# STM32F469AEH6 register map
File version: 1.0
Registers are 32-bit, access not given, reset 0x0 unless marked. A register's access mark holds for its fields unless they carry their own. Offsets are from the block's base; [hi:lo] are bit positions; {n}, {i} and the like mark numbered series.

## USART2
Base 0x40004400
Same registers: USART3 0x40004800, UART4 0x40004C00, UART5 0x40005000, UART7 0x40007800, UART8 0x40007C00, USART1 0x40011000, USART6 0x40011400
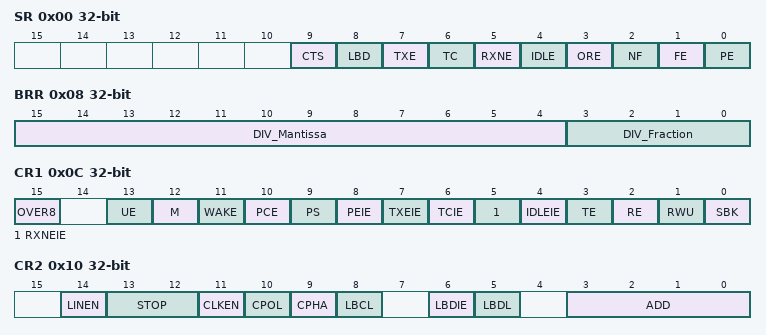
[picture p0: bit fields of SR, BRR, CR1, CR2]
0x00 SR
  [9] CTS, [8] LBD, [7] TXE, [6] TC, [5] RXNE, [4] IDLE, [3] ORE, [2] NF, [1] FE, [0] PE
0x04 DR
  [8:0] DR
0x08 BRR
  [15:4] DIV_Mantissa, [3:0] DIV_Fraction
0x0C CR1
  [15] OVER8, [13] UE, [12] M, [11] WAKE, [10] PCE, [9] PS, [8] PEIE, [7] TXEIE, [6] TCIE, [5] RXNEIE, [4] IDLEIE, [3] TE, [2] RE, [1] RWU, [0] SBK
0x10 CR2
  [14] LINEN, [13:12] STOP, [11] CLKEN, [10] CPOL, [9] CPHA, [8] LBCL, [6] LBDIE, [5] LBDL, [3:0] ADD
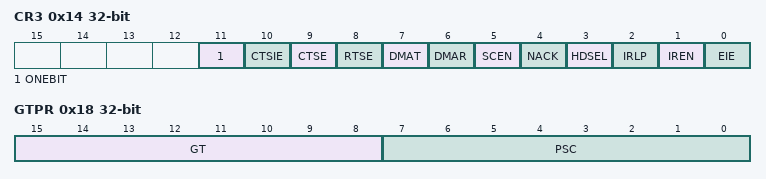
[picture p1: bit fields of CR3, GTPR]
0x14 CR3
  [11] ONEBIT, [10] CTSIE, [9] CTSE, [8] RTSE, [7] DMAT, [6] DMAR, [5] SCEN, [4] NACK, [3] HDSEL, [2] IRLP, [1] IREN, [0] EIE
0x18 GTPR
  [15:8] GT, [7:0] PSC

## I2C1
Base 0x40005400
Same registers: I2C2 0x40005800, I2C3 0x40005C00
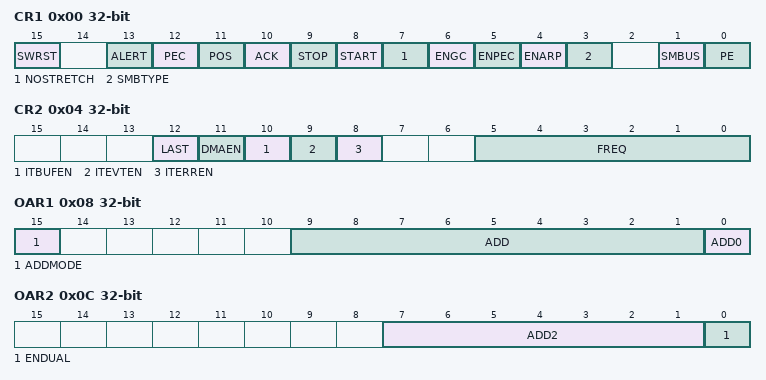
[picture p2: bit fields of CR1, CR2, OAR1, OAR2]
0x00 CR1
  [15] SWRST, [13] ALERT, [12] PEC, [11] POS, [10] ACK, [9] STOP, [8] START, [7] NOSTRETCH, [6] ENGC, [5] ENPEC, [4] ENARP, [3] SMBTYPE, [1] SMBUS, [0] PE
0x04 CR2
  [12] LAST, [11] DMAEN, [10] ITBUFEN, [9] ITEVTEN, [8] ITERREN, [5:0] FREQ
0x08 OAR1
  [15] ADDMODE, [9:1] ADD, [0] ADD0
0x0C OAR2
  [7:1] ADD2, [0] ENDUAL
0x10 DR
  [7:0] DR
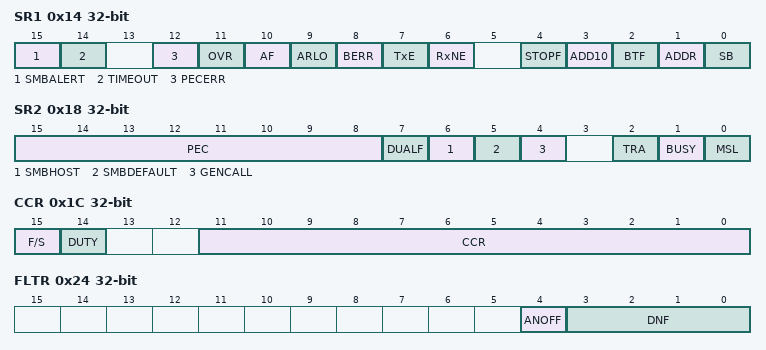
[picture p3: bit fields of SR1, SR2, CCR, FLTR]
0x14 SR1
  [15] SMBALERT, [14] TIMEOUT, [12] PECERR, [11] OVR, [10] AF, [9] ARLO, [8] BERR, [7] TxE, [6] RxNE, [4] STOPF, [3] ADD10, [2] BTF, [1] ADDR, [0] SB
0x18 SR2
  [15:8] PEC, [7] DUALF, [6] SMBHOST, [5] SMBDEFAULT, [4] GENCALL, [2] TRA, [1] BUSY, [0] MSL
0x1C CCR
  [15] F/S, [14] DUTY, [11:0] CCR
0x20 TRISE
  [5:0] TRISE
0x24 FLTR
  [4] ANOFF, [3:0] DNF

## CAN1
Base 0x40006400
Same registers: CAN2 0x40006800
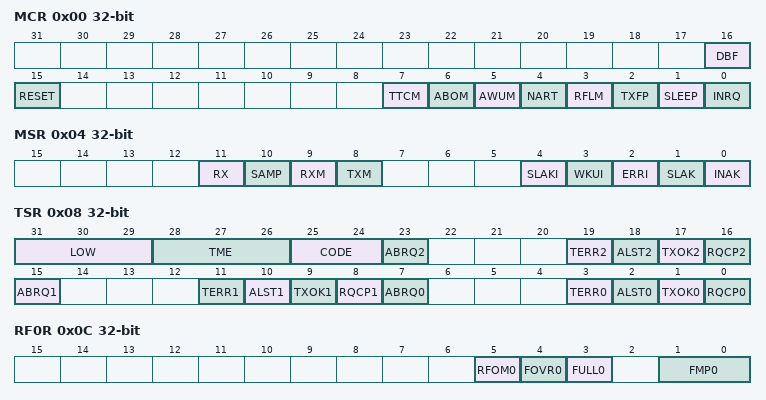
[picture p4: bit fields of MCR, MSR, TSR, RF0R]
0x00 MCR
  [16] DBF, [15] RESET, [7] TTCM, [6] ABOM, [5] AWUM, [4] NART, [3] RFLM, [2] TXFP, [1] SLEEP, [0] INRQ
0x04 MSR
  [11] RX, [10] SAMP, [9] RXM, [8] TXM, [4] SLAKI, [3] WKUI, [2] ERRI, [1] SLAK, [0] INAK
0x08 TSR
  [31:29] LOW, [28:26] TME, [25:24] CODE, [23] ABRQ2, [19] TERR2, [18] ALST2, [17] TXOK2, [16] RQCP2, [15] ABRQ1, [11] TERR1, [10] ALST1, [9] TXOK1, [8] RQCP1, [7] ABRQ0, [3] TERR0, [2] ALST0, [1] TXOK0, [0] RQCP0
0x0C RF0R
  [5] RFOM0, [4] FOVR0, [3] FULL0, [1:0] FMP0
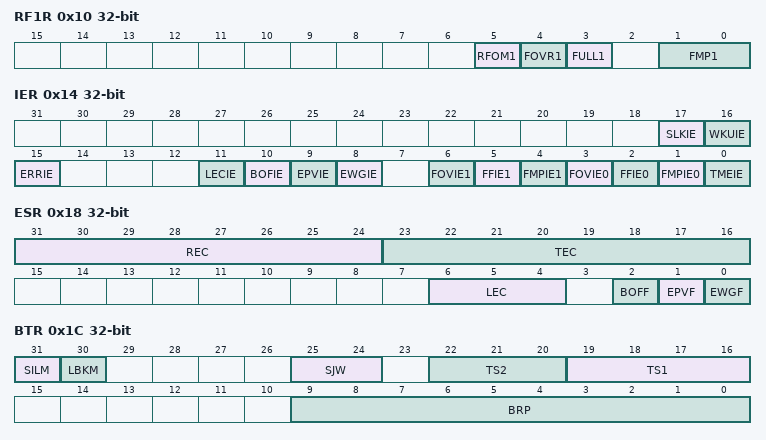
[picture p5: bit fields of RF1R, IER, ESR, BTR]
0x10 RF1R
  [5] RFOM1, [4] FOVR1, [3] FULL1, [1:0] FMP1
0x14 IER
  [17] SLKIE, [16] WKUIE, [15] ERRIE, [11] LECIE, [10] BOFIE, [9] EPVIE, [8] EWGIE, [6] FOVIE1, [5] FFIE1, [4] FMPIE1, [3] FOVIE0, [2] FFIE0, [1] FMPIE0, [0] TMEIE
0x18 ESR
  [31:24] REC, [23:16] TEC, [6:4] LEC, [2] BOFF, [1] EPVF, [0] EWGF
0x1C BTR
  [31] SILM, [30] LBKM, [25:24] SJW, [22:20] TS2, [19:16] TS1, [9:0] BRP
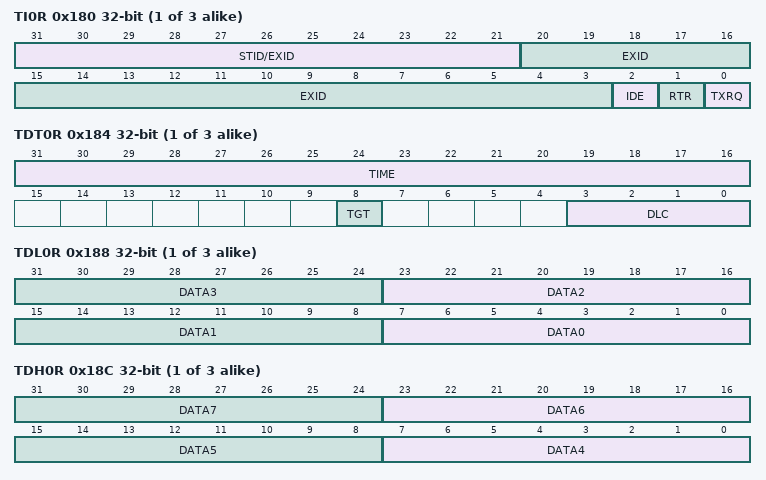
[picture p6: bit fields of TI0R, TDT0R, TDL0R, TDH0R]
{0x180+0x10*i} TI{i}R (i=0..2)
  [31:21] STID/EXID, [20:3] EXID, [2] IDE, [1] RTR, [0] TXRQ
{0x184+0x10*i} TDT{i}R (i=0..2)
  [31:16] TIME, [8] TGT, [3:0] DLC
{0x188+0x10*i} TDL{i}R (i=0..2)
  [8n+7:8n] DATA{n} (n=0..3)
{0x18C+0x10*i} TDH{i}R (i=0..2)
  [8n-25:8n-32] DATA{n} (n=4..7)
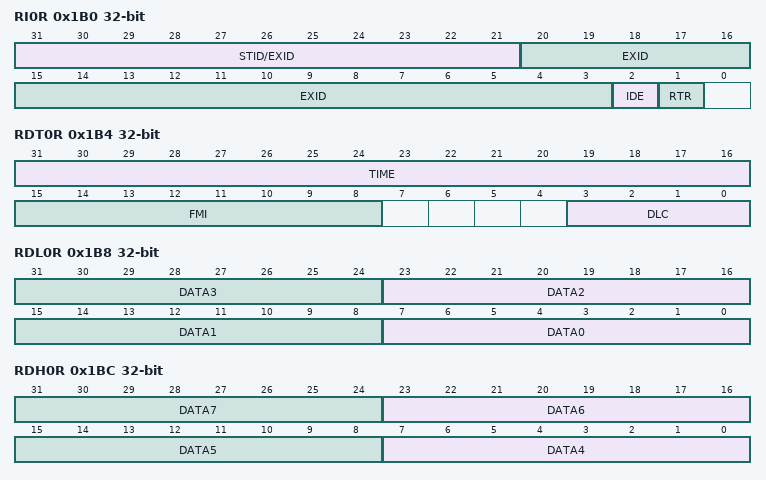
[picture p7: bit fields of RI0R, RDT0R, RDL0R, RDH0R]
0x1B0 RI0R
  [31:21] STID/EXID, [20:3] EXID, [2] IDE, [1] RTR
0x1B4 RDT0R
  [31:16] TIME, [15:8] FMI, [3:0] DLC
0x1B8 RDL0R
  [8n+7:8n] DATA{n} (n=0..3)
0x1BC RDH0R
  [8n-25:8n-32] DATA{n} (n=4..7)
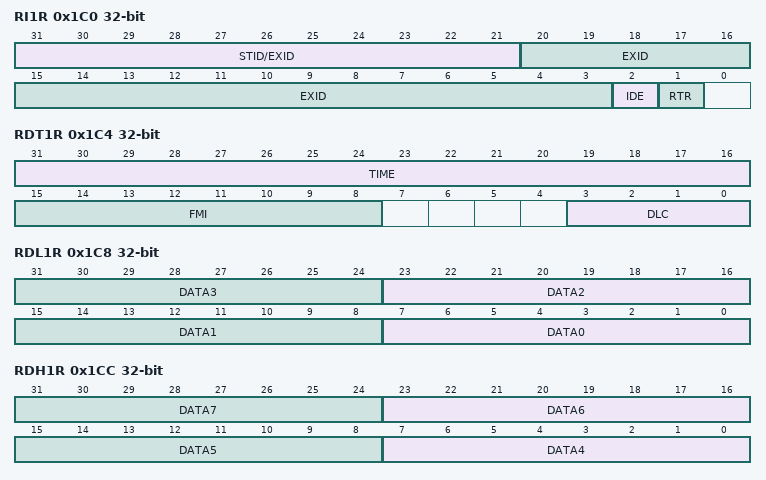
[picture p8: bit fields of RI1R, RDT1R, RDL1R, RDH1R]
0x1C0 RI1R
  [31:21] STID/EXID, [20:3] EXID, [2] IDE, [1] RTR
0x1C4 RDT1R
  [31:16] TIME, [15:8] FMI, [3:0] DLC
0x1C8 RDL1R
  [8n+7:8n] DATA{n} (n=0..3)
0x1CC RDH1R
  [8n-25:8n-32] DATA{n} (n=4..7)
0x20C FS1R
  [27:0] FSC
0x214 FFA1R
  [27:0] FFA
0x21C FA1R
  [27:0] FACT
{0x240+8i} F{i}R1 (i=0..27)
  [31:0] FB
{0x244+8i} F{i}R2 (i=0..27)
  [31:0] FB

## PWR
Base 0x40007000
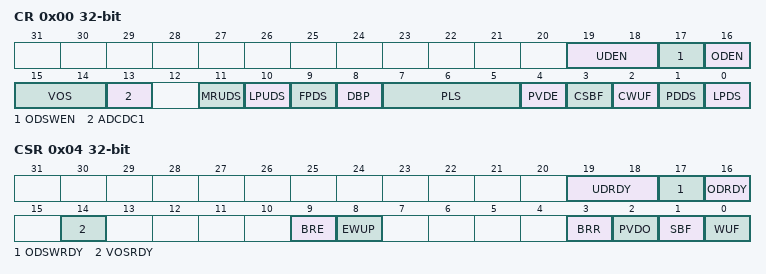
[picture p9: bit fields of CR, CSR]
0x00 CR
  [19:18] UDEN, [17] ODSWEN, [16] ODEN, [15:14] VOS, [13] ADCDC1, [11] MRUDS, [10] LPUDS, [9] FPDS, [8] DBP, [7:5] PLS, [4] PVDE, [3] CSBF, [2] CWUF, [1] PDDS, [0] LPDS
0x04 CSR
  [19:18] UDRDY, [17] ODSWRDY, [16] ODRDY, [14] VOSRDY, [9] BRE, [8] EWUP, [3] BRR, [2] PVDO, [1] SBF, [0] WUF
